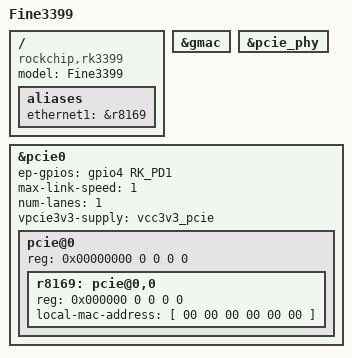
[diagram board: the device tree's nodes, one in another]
// SPDX-License-Identifier: (GPL-2.0+ OR MIT)
/dts-v1/;

#include <dt-bindings/input/linux-event-codes.h>
#include <dt-bindings/pwm/pwm.h>
#include <dt-bindings/input/input.h>
#include "rk3399.dtsi"
#include "rk3399-opp.dtsi"
#include "rk3399-bozz.dtsi"


/ {
	model = "Fine3399";
	compatible = "rockchip,rk3399";
	
	aliases {
		ethernet1 = &r8169;
	};
}

&gmac {
	status = "okay";
};

&pcie_phy {
	status = "okay";
};

&pcie0 {
	ep-gpios = <&gpio4 RK_PD1 GPIO_ACTIVE_HIGH>;
	max-link-speed = <1>;
	num-lanes = <1>;
	vpcie3v3-supply = <&vcc3v3_pcie>;

	pcie@0 {
		reg = <0x00000000 0 0 0 0>;
		#address-cells = <3>;
		#size-cells = <2>;

		r8169: pcie@0,0 {
			reg = <0x000000 0 0 0 0>;
			local-mac-address = [ 00 00 00 00 00 00 ];
		};
	};
};
